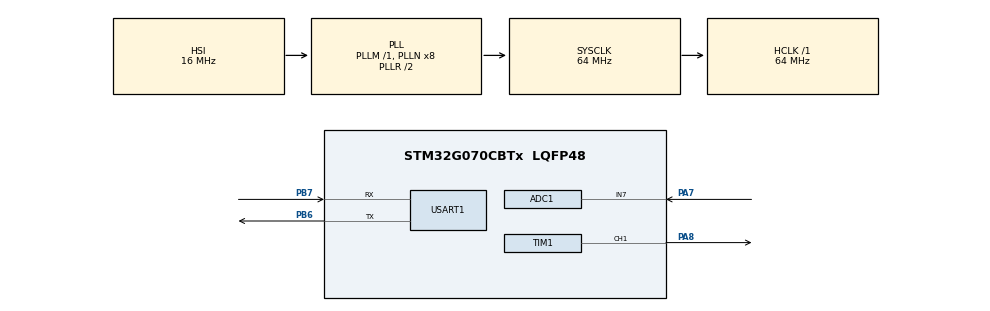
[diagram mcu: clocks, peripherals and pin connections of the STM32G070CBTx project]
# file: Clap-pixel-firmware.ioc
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ADC1.Channel-0\#ChannelRegularConversion=ADC_CHANNEL_7
ADC1.ClockPrescaler=ADC_CLOCK_ASYNC_DIV32
ADC1.NbrOfConversionFlag=1
ADC1.Rank-0\#ChannelRegularConversion=1
ADC1.SamplingTime-0\#ChannelRegularConversion=ADC_SAMPLINGTIME_COMMON_1
ADC1.SamplingTimeCommon1=ADC_SAMPLETIME_79CYCLES_5
ADC1.SamplingTimeCommon2=ADC_SAMPLETIME_79CYCLES_5
ADC1.SelectedChannel=ADC_CHANNEL_7
ADC1.master=1
Dma.ADC1.1.Direction=DMA_PERIPH_TO_MEMORY
Dma.ADC1.1.EventEnable=DISABLE
Dma.ADC1.1.Instance=DMA1_Channel6
Dma.ADC1.1.MemDataAlignment=DMA_MDATAALIGN_HALFWORD
Dma.ADC1.1.MemInc=DMA_MINC_ENABLE
Dma.ADC1.1.Mode=DMA_NORMAL
Dma.ADC1.1.PeriphDataAlignment=DMA_PDATAALIGN_HALFWORD
Dma.ADC1.1.PeriphInc=DMA_PINC_DISABLE
Dma.ADC1.1.Polarity=HAL_DMAMUX_REQ_GEN_RISING
Dma.ADC1.1.Priority=DMA_PRIORITY_HIGH
Dma.ADC1.1.RequestNumber=1
Dma.ADC1.1.SignalID=NONE
Dma.ADC1.1.SyncEnable=DISABLE
Dma.ADC1.1.SyncPolarity=HAL_DMAMUX_SYNC_NO_EVENT
Dma.ADC1.1.SyncRequestNumber=1
Dma.ADC1.1.SyncSignalID=NONE
Dma.Request0=TIM1_CH1
Dma.Request1=ADC1
Dma.TIM1_CH1.0.Direction=DMA_MEMORY_TO_PERIPH
Dma.TIM1_CH1.0.EventEnable=DISABLE
Dma.TIM1_CH1.0.Instance=DMA1_Channel1
Dma.TIM1_CH1.0.MemDataAlignment=DMA_MDATAALIGN_WORD
Dma.TIM1_CH1.0.MemInc=DMA_MINC_ENABLE
Dma.TIM1_CH1.0.Mode=DMA_NORMAL
Dma.TIM1_CH1.0.PeriphDataAlignment=DMA_PDATAALIGN_WORD
Dma.TIM1_CH1.0.PeriphInc=DMA_PINC_DISABLE
Dma.TIM1_CH1.0.Polarity=HAL_DMAMUX_REQ_GEN_RISING
Dma.TIM1_CH1.0.Priority=DMA_PRIORITY_MEDIUM
Dma.TIM1_CH1.0.RequestNumber=1
Dma.TIM1_CH1.0.SignalID=NONE
Dma.TIM1_CH1.0.SyncEnable=DISABLE
Dma.TIM1_CH1.0.SyncPolarity=HAL_DMAMUX_SYNC_NO_EVENT
Dma.TIM1_CH1.0.SyncRequestNumber=1
Dma.TIM1_CH1.0.SyncSignalID=NONE
Mcu.Family=STM32G0
Mcu.Name=STM32G070CBTx
Mcu.Package=LQFP48
NVIC.ADC1_IRQn=true\:0\:0\:false\:false\:true\:true\:true\:true
NVIC.DMA1_Ch4_7_DMAMUX1_OVR_IRQn=true\:0\:0\:false\:false\:true\:false\:true\:true
NVIC.DMA1_Channel1_IRQn=true\:0\:0\:false\:false\:true\:false\:true\:true
NVIC.TIM1_BRK_UP_TRG_COM_IRQn=true\:0\:0\:false\:false\:true\:true\:true\:true
NVIC.TIM1_CC_IRQn=true\:0\:0\:false\:false\:true\:true\:true\:true
PA13.Mode=Serial_Wire
PA13.Signal=SYS_SWDIO
PA14-BOOT0.Mode=Serial_Wire
PA14-BOOT0.Signal=SYS_SWCLK
PA7.Mode=IN7
PA7.Signal=ADC1_IN7
PA8.GPIO_PuPd=GPIO_PULLDOWN
PA8.GPIO_Speed=GPIO_SPEED_FREQ_MEDIUM
PA8.Signal=S_TIM1_CH1
PB6.Mode=Asynchronous
PB6.Signal=USART1_TX
PB7.Mode=Asynchronous
PB7.Signal=USART1_RX
ProjectManager.HeapSize=0x200
ProjectManager.StackSize=0x400
ProjectManager.TargetToolchain=CMake
RCC.ADCFreq_Value=64000000
RCC.AHBFreq_Value=64000000
RCC.CortexFreq_Value=64000000
RCC.EXTERNAL_CLOCK_VALUE=48000
RCC.HCLKFreq_Value=64000000
RCC.HSE_VALUE=8000000
RCC.HSI_VALUE=16000000
RCC.LSE_VALUE=32768
RCC.PLLP=RCC_PLLP_DIV4
RCC.SYSCLKFreq_VALUE=64000000
RCC.SYSCLKSource=RCC_SYSCLKSOURCE_PLLCLK
RCC.VCOOutputFreq_Value=128000000
SH.S_TIM1_CH1.0=TIM1_CH1,PWM Generation1 CH1
TIM1.AutoReloadPreload=TIM_AUTORELOAD_PRELOAD_DISABLE
TIM1.Channel-PWM\ Generation1\ CH1=TIM_CHANNEL_1
TIM1.OC1Preload_PWM=ENABLE
TIM1.OCFastMode_PWM-PWM\ Generation1\ CH1=TIM_OCFAST_DISABLE
TIM1.OCIdleState_1=TIM_OCIDLESTATE_SET
TIM1.OCMode_PWM-PWM\ Generation1\ CH1=TIM_OCMODE_PWM1
TIM1.OCPolarity_1=TIM_OCPOLARITY_HIGH
TIM1.Period=79
TIM1.Prescaler=0
USART1.VirtualMode-Asynchronous=VM_ASYNC
board=custom

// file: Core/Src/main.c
/* USER CODE BEGIN Header */
/**
 ******************************************************************************
 * @file           : main.c
 * @brief          : Main program body
 ******************************************************************************
 * @attention
 *
 * Copyright (c) 2025 STMicroelectronics.
 * All rights reserved.
 *
 * This software is licensed under terms that can be found in the LICENSE file
 * in the root directory of this software component.
 * If no LICENSE file comes with this software, it is provided AS-IS.
 *
 ******************************************************************************
 */
/* USER CODE END Header */
#include "main.h"
#include "adc.h"
#include "dma.h"
#include "tim.h"
#include "usart.h"
#include "gpio.h"

/* USER CODE BEGIN Includes */
#include <stdio.h>
#include "control.h"
/* USER CODE END Includes */

void SystemClock_Config(void);

int main(void)
{

  /* MCU Configuration--------------------------------------------------------*/

  /* Reset of all peripherals, Initializes the Flash interface and the Systick. */
  HAL_Init();

  /* Configure the system clock */
  SystemClock_Config();

  /* Initialize all configured peripherals */
  MX_GPIO_Init();
  MX_DMA_Init();
  MX_USART1_UART_Init();
  MX_ADC1_Init();
  MX_TIM1_Init();
  /* USER CODE BEGIN 2 */
  Control_Init();
  /* USER CODE END 2 */

  /* Infinite loop */
  /* USER CODE BEGIN WHILE */
  while (1)
  {
    Control_Loop();
    /* USER CODE END WHILE */

  }
}

void SystemClock_Config(void)
{
  RCC_OscInitTypeDef RCC_OscInitStruct = {0};
  RCC_ClkInitTypeDef RCC_ClkInitStruct = {0};

  /** Configure the main internal regulator output voltage
  */
  HAL_PWREx_ControlVoltageScaling(PWR_REGULATOR_VOLTAGE_SCALE1);

  /** Initializes the RCC Oscillators according to the specified parameters
  * in the RCC_OscInitTypeDef structure.
  */
  RCC_OscInitStruct.OscillatorType = RCC_OSCILLATORTYPE_HSI;
  RCC_OscInitStruct.HSIState = RCC_HSI_ON;
  RCC_OscInitStruct.HSIDiv = RCC_HSI_DIV1;
  RCC_OscInitStruct.HSICalibrationValue = RCC_HSICALIBRATION_DEFAULT;
  RCC_OscInitStruct.PLL.PLLState = RCC_PLL_ON;
  RCC_OscInitStruct.PLL.PLLSource = RCC_PLLSOURCE_HSI;
  RCC_OscInitStruct.PLL.PLLM = RCC_PLLM_DIV1;
  RCC_OscInitStruct.PLL.PLLN = 8;
  RCC_OscInitStruct.PLL.PLLP = RCC_PLLP_DIV4;
  RCC_OscInitStruct.PLL.PLLR = RCC_PLLR_DIV2;
  if (HAL_RCC_OscConfig(&RCC_OscInitStruct) != HAL_OK)
  {
    Error_Handler();
  }

  /** Initializes the CPU, AHB and APB buses clocks
  */
  RCC_ClkInitStruct.ClockType = RCC_CLOCKTYPE_HCLK|RCC_CLOCKTYPE_SYSCLK
                              |RCC_CLOCKTYPE_PCLK1;
  RCC_ClkInitStruct.SYSCLKSource = RCC_SYSCLKSOURCE_PLLCLK;
  RCC_ClkInitStruct.AHBCLKDivider = RCC_SYSCLK_DIV1;
  RCC_ClkInitStruct.APB1CLKDivider = RCC_HCLK_DIV1;

  if (HAL_RCC_ClockConfig(&RCC_ClkInitStruct, FLASH_LATENCY_2) != HAL_OK)
  {
    Error_Handler();
  }
}

void Error_Handler(void)
{
  __disable_irq();
  while (1)
  {
  }
}

#ifdef  USE_FULL_ASSERT
/**
  * @brief  Reports the name of the source file and the source line number
  *         where the assert_param error has occurred.
  * @param  file: pointer to the source file name
  * @param  line: assert_param error line source number
  * @retval None
  */
void assert_failed(uint8_t *file, uint32_t line)
{
  /* USER CODE BEGIN 6 */
  printf("Assert failed: file %s on line %lu\r\n", file, line);
  /* USER CODE END 6 */
}
#endif /* USE_FULL_ASSERT */
